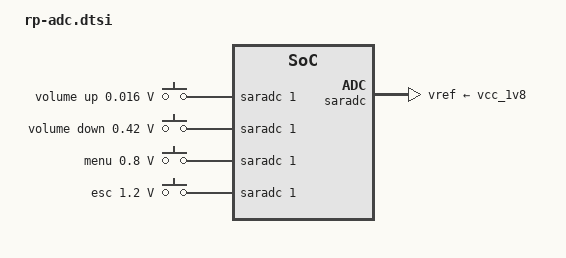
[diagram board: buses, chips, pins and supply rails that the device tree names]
/{
    adc_keys: adc-keys {
        compatible = "adc-keys";
        io-channels = <&saradc 1>;
        io-channel-names = "buttons";
        keyup-threshold-microvolt = <1800000>;
        poll-interval = <100>;
        
        vol-up-key {
            label = "volume up";
            linux,code = <KEY_VOLUMEUP>;
            press-threshold-microvolt = <16000>;
        };
        
        vol-down-key {
            label = "volume down";
            linux,code = <KEY_VOLUMEDOWN>;
            press-threshold-microvolt = <420000>;
        };
        
        menu-key {
            label = "menu";
            linux,code = <KEY_MENU>;
            press-threshold-microvolt = <800000>;
        };
        
        esc-key {
            label = "esc";
            linux,code = <KEY_ESC>;
            press-threshold-microvolt = <1200000>;
        };
    };
};

&saradc {
    vref-supply = <&vcc_1v8>;
    status = "okay";
};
